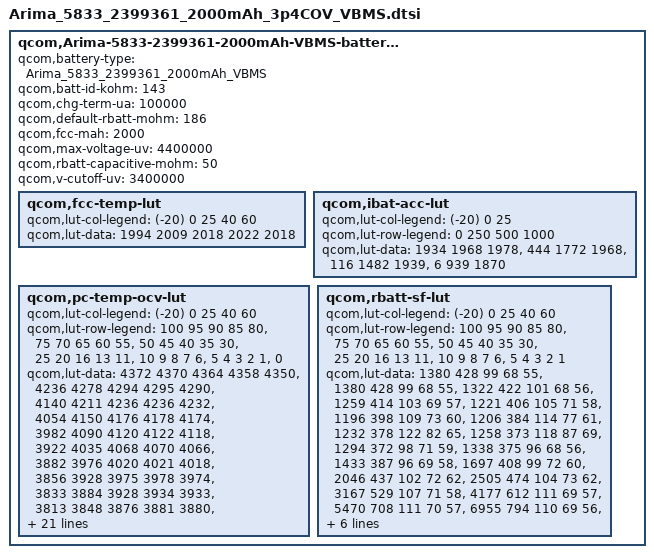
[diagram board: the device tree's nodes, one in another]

qcom,Arima-5833-2399361-2000mAh-VBMS-batterydata {
	qcom,battery-type = "Arima_5833_2399361_2000mAh_VBMS";
	qcom,batt-id-kohm = <143>;
	qcom,chg-term-ua = <100000>;
	qcom,default-rbatt-mohm = <186>;
	qcom,fcc-mah = <2000>;
	qcom,max-voltage-uv = <4400000>;
	qcom,rbatt-capacitive-mohm = <50>;
	qcom,v-cutoff-uv = <3400000>;

	qcom,fcc-temp-lut {
		qcom,lut-col-legend = <(-20) 0 25 40 60>;
		qcom,lut-data = <1994 2009 2018 2022 2018>;
	};

	qcom,ibat-acc-lut {
		qcom,lut-col-legend = <(-20) 0 25>;
		qcom,lut-row-legend = <0 250 500 1000>;
		qcom,lut-data = <1934 1968 1978>,
				<444 1772 1968>,
				<116 1482 1939>,
				<6 939 1870>;
	};

	qcom,pc-temp-ocv-lut {
		qcom,lut-col-legend = <(-20) 0 25 40 60>;
		qcom,lut-row-legend = <100 95 90 85 80>,
					<75 70 65 60 55>,
					<50 45 40 35 30>,
					<25 20 16 13 11>,
					<10 9 8 7 6>,
					<5 4 3 2 1>,
					<0>;
		qcom,lut-data = <4372 4370 4364 4358 4350>,
				<4236 4278 4294 4295 4290>,
				<4140 4211 4236 4236 4232>,
				<4054 4150 4176 4178 4174>,
				<3982 4090 4120 4122 4118>,
				<3922 4035 4068 4070 4066>,
				<3882 3976 4020 4021 4018>,
				<3856 3928 3975 3978 3974>,
				<3833 3884 3928 3934 3933>,
				<3813 3848 3876 3881 3880>,
				<3794 3817 3844 3847 3847>,
				<3774 3795 3819 3823 3823>,
				<3754 3779 3800 3803 3803>,
				<3733 3764 3783 3786 3785>,
				<3710 3746 3769 3770 3766>,
				<3684 3727 3755 3752 3740>,
				<3654 3708 3734 3730 3716>,
				<3624 3692 3706 3702 3688>,
				<3596 3678 3685 3680 3669>,
				<3574 3668 3679 3677 3667>,
				<3563 3660 3678 3676 3666>,
				<3550 3653 3675 3675 3664>,
				<3534 3644 3672 3672 3662>,
				<3518 3632 3668 3670 3658>,
				<3498 3616 3658 3658 3640>,
				<3474 3594 3630 3624 3598>,
				<3443 3558 3580 3570 3543>,
				<3401 3506 3512 3501 3470>,
				<3336 3428 3418 3406 3367>,
				<3234 3298 3268 3248 3190>,
				<3000 3000 3000 3000 3000>;
	};

	qcom,rbatt-sf-lut {
		qcom,lut-col-legend = <(-20) 0 25 40 60>;
		qcom,lut-row-legend = <100 95 90 85 80>,
					<75 70 65 60 55>,
					<50 45 40 35 30>,
					<25 20 16 13 11>,
					<10 9 8 7 6>,
					<5 4 3 2 1>;
		qcom,lut-data = <1380 428 99 68 55>,
				<1380 428 99 68 55>,
				<1322 422 101 68 56>,
				<1259 414 103 69 57>,
				<1221 406 105 71 58>,
				<1196 398 109 73 60>,
				<1206 384 114 77 61>,
				<1232 378 122 82 65>,
				<1258 373 118 87 69>,
				<1294 372 98 71 59>,
				<1338 375 96 68 56>,
				<1433 387 96 69 58>,
				<1697 408 99 72 60>,
				<2046 437 102 72 62>,
				<2505 474 104 73 62>,
				<3167 529 107 71 58>,
				<4177 612 111 69 57>,
				<5470 708 111 70 57>,
				<6955 794 110 69 56>,
				<8270 826 112 70 58>,
				<8649 830 115 71 59>,
				<9662 878 120 73 60>,
				<11170 936 126 76 61>,
				<13231 1006 135 79 63>,
				<15937 1096 145 81 60>,
				<19835 1301 146 76 60>,
				<25812 1747 148 79 62>,
				<35709 2576 163 85 68>,
				<54419 4380 197 98 76>,
				<93818 8759 282 196 152>;
	};
};
